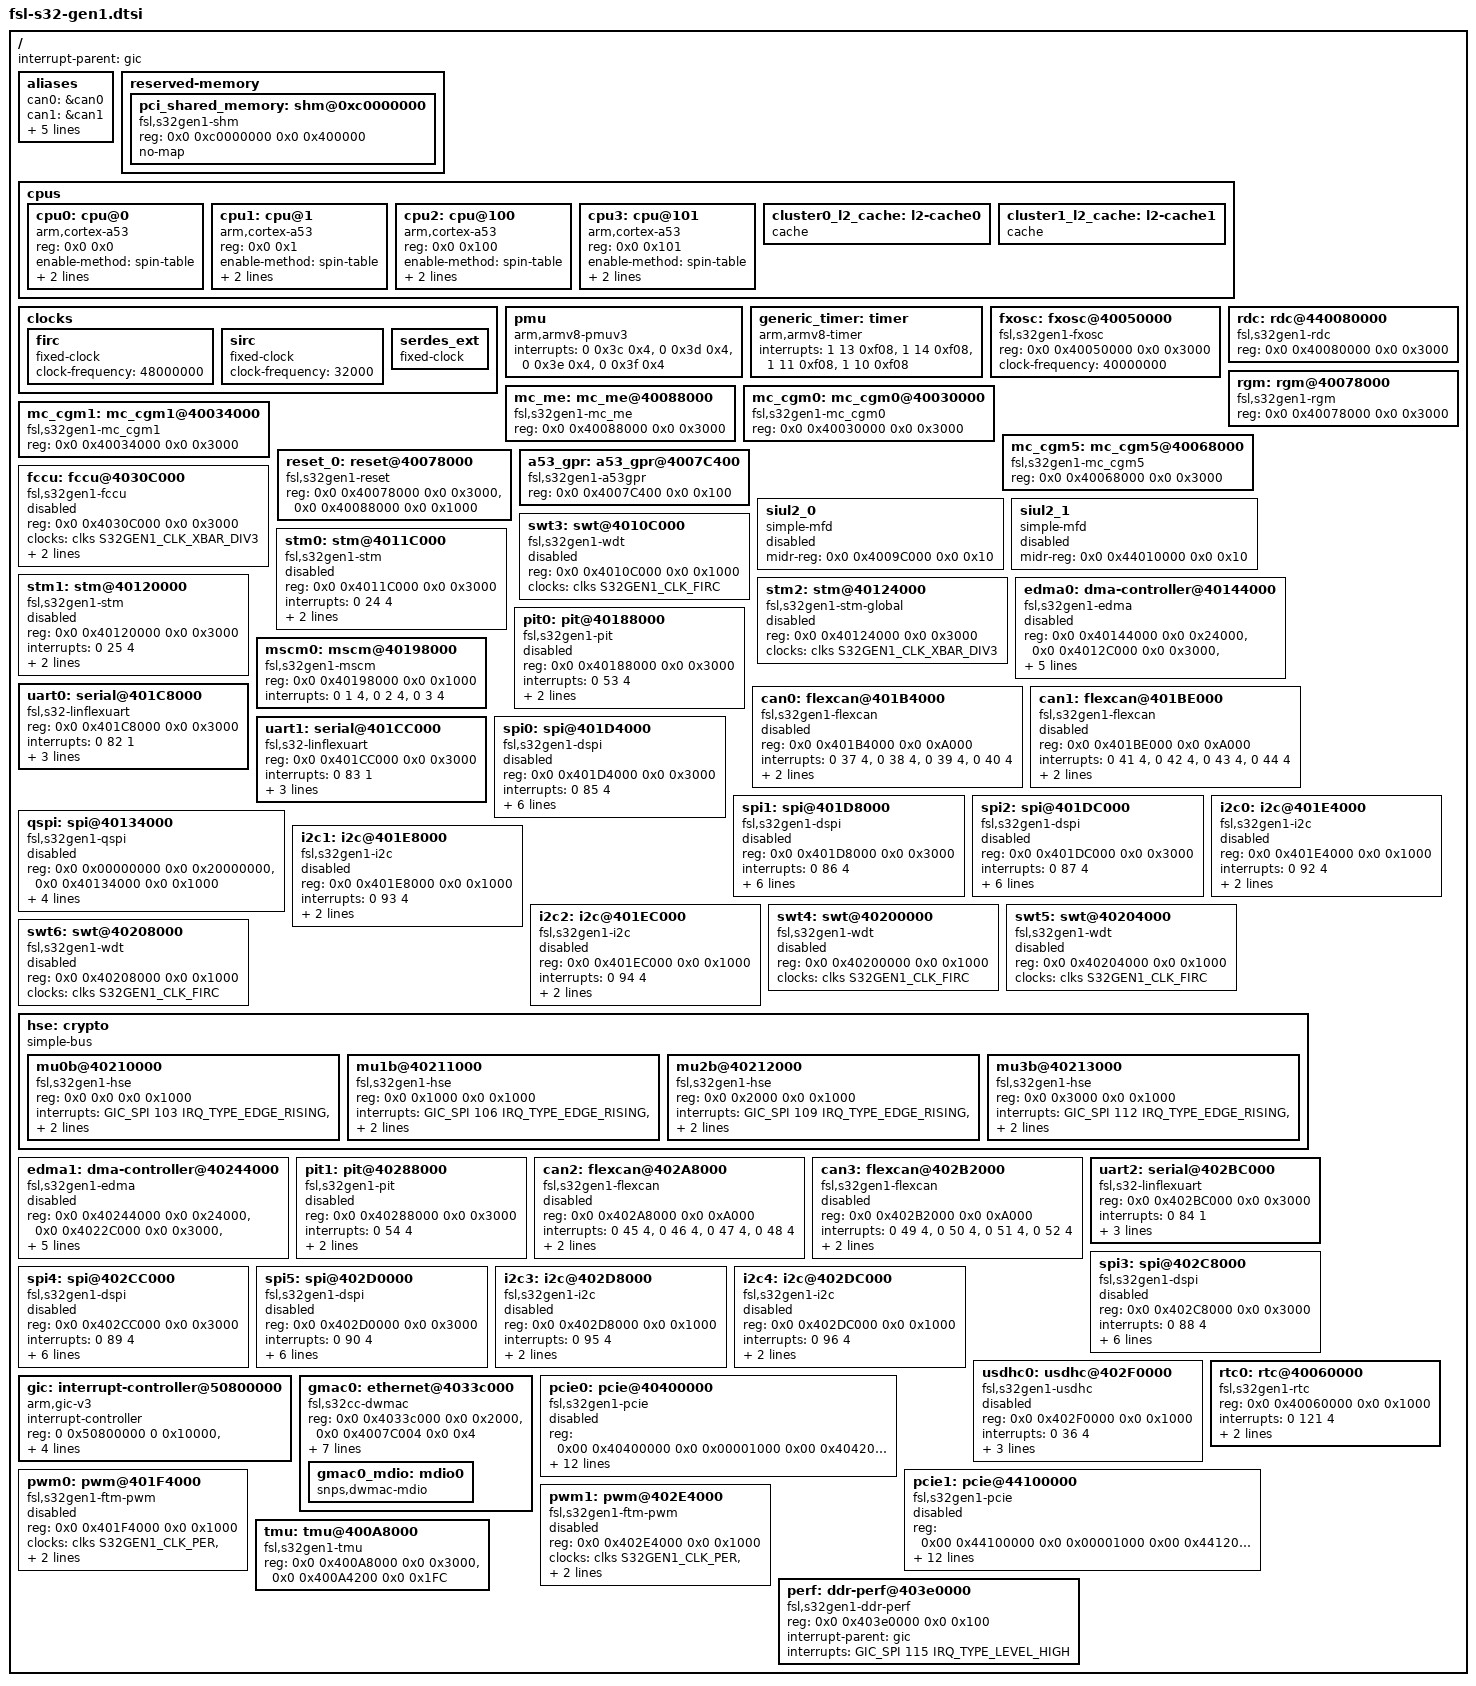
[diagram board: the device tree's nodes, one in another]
/*
 * Copyright 2017-2020 NXP
 *
 * This program is free software; you can redistribute it and/or modify
 * it under the terms of the GNU General Public License as published by
 * the Free Software Foundation; either version 2 of the License, or
 * (at your option) any later version.
 */

#include <dt-bindings/interrupt-controller/arm-gic.h>
#include <dt-bindings/clock/s32gen1-clock.h>

/memreserve/ 0x8000fff8 0x00010000;

/ {
	interrupt-parent = <&gic>;
	#address-cells = <2>;
	#size-cells = <2>;

	aliases {
		can0 = &can0;
		can1 = &can1;
		can2 = &can2;
		can3 = &can3;

		serial0 = &uart0;
		serial1 = &uart1;
		serial2 = &uart2;
	};

	reserved-memory {
		#address-cells = <2>;
		#size-cells = <2>;
		ranges;

		/* 4Mb shared memory for PCIe shared mem transfers, EP mode */
		pci_shared_memory: shm@0xc0000000 {
			compatible = "fsl,s32gen1-shm";
			reg = <0x0 0xc0000000 0x0 0x400000>;    /* 4 MB */
			no-map;
		};
	};

	cpus {
		#address-cells = <2>;
		#size-cells = <0>;

		cpu0: cpu@0 {
			device_type = "cpu";
			compatible = "arm,cortex-a53";
			reg = <0x0 0x0>;
			enable-method = "spin-table";
			cpu-release-addr = <0x0 0x00>;
		};
		cpu1: cpu@1 {
			device_type = "cpu";
			compatible = "arm,cortex-a53";
			reg = <0x0 0x1>;
			enable-method = "spin-table";
			cpu-release-addr = <0x0 0x00>;
		};
		cpu2: cpu@100 {
			device_type = "cpu";
			compatible = "arm,cortex-a53";
			reg = <0x0 0x100>;
			enable-method = "spin-table";
			cpu-release-addr = <0x0 0x00>;
		};
		cpu3: cpu@101 {
			device_type = "cpu";
			compatible = "arm,cortex-a53";
			reg = <0x0 0x101>;
			enable-method = "spin-table";
			cpu-release-addr = <0x0 0x00>;
		};

		cluster0_l2_cache: l2-cache0 {
			compatible = "cache";
			status = "disabled";
		};

		cluster1_l2_cache: l2-cache1 {
			compatible = "cache";
			status = "disabled";
		};

	};

	clocks {
		#address-cells = <1>;
		#size-cells = <0>;

		firc {
			compatible = "fixed-clock";
			clock-frequency = <48000000>;
			#clock-cells = <0>;
		};
		sirc {
			compatible = "fixed-clock";
			clock-frequency = <32000>;
			#clock-cells = <0>;
		};
		serdes_ext: serdes_ext {
			compatible = "fixed-clock";
			#clock-cells = <0>;
		};
	};

	pmu {
		compatible = "arm,armv8-pmuv3";
		interrupts = <0 0x3c 0x4>,
			     <0 0x3d 0x4>,
			     <0 0x3e 0x4>,
			     <0 0x3f 0x4>;
	};

	generic_timer: timer {
		compatible = "arm,armv8-timer";
		interrupts = <1 13 0xf08>,
			     <1 14 0xf08>,
			     <1 11 0xf08>,
			     <1 10 0xf08>;
	};

	fxosc: fxosc@40050000 {
		compatible = "fsl,s32gen1-fxosc";
		reg = <0x0 0x40050000 0x0 0x3000>;
		clock-frequency = <40000000>;
		#clock-cells = <1>;
	};

	rdc: rdc@440080000 {
		compatible = "fsl,s32gen1-rdc";
		reg = <0x0 0x40080000 0x0 0x3000>;
	};

	rgm: rgm@40078000 {
		compatible = "fsl,s32gen1-rgm";
		reg = <0x0 0x40078000 0x0 0x3000>;
	};

	mc_me: mc_me@40088000 {
		compatible = "fsl,s32gen1-mc_me";
		reg = <0x0 0x40088000 0x0 0x3000>;
	};

	mc_cgm0: mc_cgm0@40030000 {
		compatible = "fsl,s32gen1-mc_cgm0";
		reg = <0x0 0x40030000 0x0 0x3000>;
	};

	mc_cgm1: mc_cgm1@40034000 {
		compatible = "fsl,s32gen1-mc_cgm1";
		reg = <0x0 0x40034000 0x0 0x3000>;
	};

	mc_cgm5: mc_cgm5@40068000 {
		compatible = "fsl,s32gen1-mc_cgm5";
		reg = <0x0 0x40068000 0x0 0x3000>;
	};

	reset_0: reset@40078000 {
		compatible = "fsl,s32gen1-reset";
		      /* MC RGM */
		reg = <0x0 0x40078000 0x0 0x3000>,
		      /* MC ME */
		      <0x0 0x40088000 0x0 0x1000>;
	};

	a53_gpr: a53_gpr@4007C400 {
		compatible = "fsl,s32gen1-a53gpr";
		reg = <0x0 0x4007C400 0x0 0x100>;
	};

	fccu: fccu@4030C000 {
		compatible = "fsl,s32gen1-fccu";
		reg = <0x0 0x4030C000 0x0 0x3000>;
		clocks = <&clks S32GEN1_CLK_XBAR_DIV3>;
		clock-names = "fccu";
		/* Address offset and configuration value for */
		/* NCF_E1 and NCFS_CFG2*/
		cfg_reg_off = <0x98 0x54>;
		cfg_reg_val = <0x78 0x1540>;
		status = "disabled";
	};

	siul2_0 {
		compatible = "simple-mfd";
		#address-cells = <2>;
		#size-cells = <2>;
		/* MIDR registers
		 * They physically exist in EIRQ
		 * addr space but they don't belong
		 * to GPIO
		 */
		midr-reg = <0x0 0x4009C000 0x0 0x10>;
		status = "disabled";
	};

	siul2_1 {
		compatible = "simple-mfd";
		#address-cells = <2>;
		#size-cells = <2>;
		/* MIDR registers
		 * They physically exist in EIRQ
		 * addr space but they don't belong
		 * to GPIO
		 */
		midr-reg = <0x0 0x44010000 0x0 0x10>;
		status = "disabled";
	};

	swt3: swt@4010C000 {
		compatible = "fsl,s32gen1-wdt";
		reg = <0x0 0x4010C000 0x0 0x1000>;
		clocks = <&clks S32GEN1_CLK_FIRC>;
		clock-names = "swt";
		status = "disabled";
	};

	stm0: stm@4011C000{
		compatible = "fsl,s32gen1-stm";
		reg = <0x0 0x4011C000 0x0 0x3000>;
		interrupts= <0 24 4>;
		clocks = <&clks S32GEN1_CLK_XBAR_DIV3>;
		clock-names = "stm";
		cpu = <2>;
		status = "disabled";
	};

	stm1: stm@40120000{
		compatible = "fsl,s32gen1-stm";
		reg = <0x0 0x40120000 0x0 0x3000>;
		interrupts= <0 25 4>;
		clocks = <&clks S32GEN1_CLK_XBAR_DIV3>;
		clock-names = "stm";
		cpu = <3>;
		status = "disabled";
	};

	stm2: stm@40124000{
		compatible = "fsl,s32gen1-stm-global";
		reg = <0x0 0x40124000 0x0 0x3000>;
		clocks = <&clks S32GEN1_CLK_XBAR_DIV3>;
		clock-names = "stm";
		status = "disabled";
	};

	edma0: dma-controller@40144000 {
		#dma-cells = <2>;
		compatible = "fsl,s32gen1-edma";
		reg = <0x0 0x40144000 0x0 0x24000>,
		      <0x0 0x4012C000 0x0 0x3000>,
		      <0x0 0x40130000 0x0 0x3000>;
		dma-channels = <32>;
		interrupts = <0 8 4>,
			     <0 9 4>,
			     <0 10 4>;
		interrupt-names = "edma-tx_0-15",
				  "edma-tx_16-31",
				  "edma-err";
		clock-names = "dmamux0", "dmamux1";
		clocks = <&clks S32GEN1_CLK_XBAR>,
			 <&clks S32GEN1_CLK_XBAR>;
		status = "disabled";
	};

	pit0: pit@40188000{
		compatible = "fsl,s32gen1-pit";
		reg = <0x0 0x40188000 0x0 0x3000>;
		interrupts= <0 53 4>;
		clocks = <&clks S32GEN1_CLK_XBAR_DIV3>;
		clock-names = "pit";
		cpu = <0>;
		status = "disabled";
	};

	mscm0: mscm@40198000  {
		compatible = "fsl,s32gen1-mscm";

		reg = <0x0 0x40198000 0x0 0x1000>;

		/* CPU2CPU interrupts */
		interrupts = <0 1 4>, // CPU to M7/A53/R52 interrupt#0 (GIC 33)
			     <0 2 4>, // CPU to M7/A53/R52 interrupt#1 (GIC 34)
			     <0 3 4>; // CPU to M7/A53/R52 interrupt#2 (GIC 35)
	};

	can0: flexcan@401B4000{
		compatible = "fsl,s32gen1-flexcan";
		reg = <0x0 0x401B4000 0x0 0xA000>;
		interrupts = <0 37 4>,
			     <0 38 4>,
			     <0 39 4>,
			     <0 40 4>;
		interrupt-names = "state", "berr", "mb_0-7", "mb_8-127";
		clocks = <&clks S32GEN1_CLK_CAN>,
			 <&clks S32GEN1_CLK_XBAR_DIV3>;
		clock-names = "per", "ipg";
		status = "disabled";
	};

	can1: flexcan@401BE000{
		compatible = "fsl,s32gen1-flexcan";
		reg = <0x0 0x401BE000 0x0 0xA000>;
		interrupts = <0 41 4>,
			     <0 42 4>,
			     <0 43 4>,
			     <0 44 4>;
		interrupt-names = "state", "berr", "mb_0-7", "mb_8-127";
		clocks = <&clks S32GEN1_CLK_CAN>,
			 <&clks S32GEN1_CLK_XBAR_DIV3>;
		clock-names = "per", "ipg";
		status = "disabled";
	};

	uart0:serial@401C8000 {
		compatible = "fsl,s32-linflexuart";
		reg = <0x0 0x401C8000 0x0 0x3000>;
		interrupts = <0 82 1>;
		clocks = <&clks S32GEN1_CLK_LIN_BAUD>,
			 <&clks S32GEN1_CLK_LIN>;
		clock-names = "lin", "ipg";
		dmas = <&edma0 0 4>,
		       <&edma0 0 3>;
		dma-names = "rx", "tx";
	};

	uart1:serial@401CC000 {
		compatible = "fsl,s32-linflexuart";
		reg = <0x0 0x401CC000 0x0 0x3000>;
		interrupts = <0 83 1>;
		clocks = <&clks S32GEN1_CLK_LIN_BAUD>,
			 <&clks S32GEN1_CLK_LIN>;
		clock-names = "lin", "ipg";
		dmas = <&edma0 0 6>,
		       <&edma0 0 5>;
		dma-names = "rx", "tx";
	};

	spi0: spi@401D4000 {
		compatible = "fsl,s32gen1-dspi";
		reg = <0x0 0x401D4000 0x0 0x3000>;
		interrupts = <0 85 4>;
		clocks = <&clks S32GEN1_CLK_DSPI>;
		clock-names = "dspi";
		spi-num-chipselects = <8>;
		bus-num = <0>;
		spi-fifo-size = <5>;
		spi-cpol;
		spi-cpha;
		status = "disabled";
	};

	spi1: spi@401D8000 {
		compatible = "fsl,s32gen1-dspi";
		reg = <0x0 0x401D8000 0x0 0x3000>;
		interrupts = <0 86 4>;
		clocks = <&clks S32GEN1_CLK_DSPI>;
		clock-names = "dspi";
		spi-num-chipselects = <5>;
		bus-num = <1>;
		spi-fifo-size = <5>;
		spi-cpol;
		spi-cpha;
		status = "disabled";
	};

	spi2: spi@401DC000 {
		compatible = "fsl,s32gen1-dspi";
		reg = <0x0 0x401DC000 0x0 0x3000>;
		interrupts = <0 87 4>;
		clocks = <&clks S32GEN1_CLK_DSPI>;
		clock-names = "dspi";
		spi-num-chipselects = <5>;
		bus-num = <2>;
		spi-fifo-size = <5>;
		spi-cpol;
		spi-cpha;
		status = "disabled";
	};

	qspi: spi@40134000 {
		compatible = "fsl,s32gen1-qspi";
		#address-cells = <1>;
		#size-cells = <0>;
		reg = <0x0 0x00000000 0x0 0x20000000>,
			<0x0 0x40134000 0x0 0x1000>;
		reg-names = "QuadSPI-memory", "QuadSPI";
		interrupts = <0 32 4>;
		clocks = <&clks S32GEN1_CLK_QSPI_SEL>,
			   <&clks S32GEN1_CLK_QSPI_2X>,
			   <&clks S32GEN1_CLK_QSPI_1X>;
		clock-names = "qspi_en", "qspi";
		status = "disabled";
	};

	i2c0: i2c@401E4000 {
		#address-cells = <1>;
		#size-cells = <0>;
		compatible = "fsl,s32gen1-i2c";
		reg = <0x0 0x401E4000 0x0 0x1000>;
		interrupts =<0 92 4>;
		clocks = <&clks S32GEN1_CLK_XBAR_DIV3>;
		clock-names = "ipg";
		dmas = <&edma0 0 16>,
		       <&edma0 0 17>;
		dma-names = "rx","tx";
		status = "disabled";
	};

	i2c1: i2c@401E8000 {
		#address-cells = <1>;
		#size-cells = <0>;
		compatible = "fsl,s32gen1-i2c";
		reg = <0x0 0x401E8000 0x0 0x1000>;
		interrupts =<0 93 4>;
		clocks = <&clks S32GEN1_CLK_XBAR_DIV3>;
		clock-names = "ipg";
		dmas = <&edma0 0 18>,
		       <&edma0 0 19>;
		dma-names = "rx","tx";
		status = "disabled";
	};

	i2c2: i2c@401EC000 {
		#address-cells = <1>;
		#size-cells = <0>;
		compatible = "fsl,s32gen1-i2c";
		reg = <0x0 0x401EC000 0x0 0x1000>;
		interrupts =<0 94 4>;
		clocks = <&clks S32GEN1_CLK_XBAR_DIV3>;
		clock-names = "ipg";
		dmas = <&edma1 1 16>,
		       <&edma1 1 17>;
		dma-names = "rx","tx";
		status = "disabled";
	};

	swt4: swt@40200000 {
		compatible = "fsl,s32gen1-wdt";
		reg = <0x0 0x40200000 0x0 0x1000>;
		clocks = <&clks S32GEN1_CLK_FIRC>;
		clock-names = "swt";
		status = "disabled";
	};

	swt5: swt@40204000 {
		compatible = "fsl,s32gen1-wdt";
		reg = <0x0 0x40204000 0x0 0x1000>;
		clocks = <&clks S32GEN1_CLK_FIRC>;
		clock-names = "swt";
		status = "disabled";
	};

	swt6: swt@40208000 {
		compatible = "fsl,s32gen1-wdt";
		reg = <0x0 0x40208000 0x0 0x1000>;
		clocks = <&clks S32GEN1_CLK_FIRC>;
		clock-names = "swt";
		status = "disabled";
	};

	hse: crypto {
		compatible = "simple-bus";
		#address-cells = <2>;
		#size-cells = <2>;
		#interrupt-cells = <3>;
		ranges = <0x0 0x0 0x0 0x40210000 0x0 0x4000>;

		mu0b@40210000 {
			compatible = "fsl,s32gen1-hse";
			reg = <0x0 0x0 0x0 0x1000>;
			interrupts = <GIC_SPI 103 IRQ_TYPE_EDGE_RISING>, /* GIC 135 */
			             <GIC_SPI 104 IRQ_TYPE_EDGE_RISING>, /* GIC 136 */
			             <GIC_SPI 105 IRQ_TYPE_EDGE_RISING>; /* GIC 137 */
			interrupt-names = "hse-mu0b-ack",
			                  "hse-mu0b-rx",
			                  "hse-mu0b-err";
		};
		mu1b@40211000 {
			compatible = "fsl,s32gen1-hse";
			reg = <0x0 0x1000 0x0 0x1000>;
			interrupts = <GIC_SPI 106 IRQ_TYPE_EDGE_RISING>, /* GIC 138 */
			             <GIC_SPI 107 IRQ_TYPE_EDGE_RISING>, /* GIC 139 */
			             <GIC_SPI 108 IRQ_TYPE_EDGE_RISING>; /* GIC 140 */
			interrupt-names = "hse-mu1b-ack",
			                  "hse-mu1b-rx",
			                  "hse-mu1b-err";
		};
		mu2b@40212000 {
			compatible = "fsl,s32gen1-hse";
			reg = <0x0 0x2000 0x0 0x1000>;
			interrupts = <GIC_SPI 109 IRQ_TYPE_EDGE_RISING>, /* GIC 141 */
			             <GIC_SPI 110 IRQ_TYPE_EDGE_RISING>, /* GIC 142 */
			             <GIC_SPI 111 IRQ_TYPE_EDGE_RISING>; /* GIC 143 */
			interrupt-names = "hse-mu2b-ack",
			                  "hse-mu2b-rx",
			                  "hse-mu2b-err";
		};
		mu3b@40213000 {
			compatible = "fsl,s32gen1-hse";
			reg = <0x0 0x3000 0x0 0x1000>;
			interrupts = <GIC_SPI 112 IRQ_TYPE_EDGE_RISING>, /* GIC 144 */
			             <GIC_SPI 113 IRQ_TYPE_EDGE_RISING>, /* GIC 145 */
			             <GIC_SPI 114 IRQ_TYPE_EDGE_RISING>; /* GIC 146 */
			interrupt-names = "hse-mu3b-ack",
			                  "hse-mu3b-rx",
			                  "hse-mu3b-err";
		};
	};

	edma1: dma-controller@40244000 {
		#dma-cells = <2>;
		compatible = "fsl,s32gen1-edma";
		reg = <0x0 0x40244000 0x0 0x24000>,
		      <0x0 0x4022C000 0x0 0x3000>,
		      <0x0 0x40230000 0x0 0x3000>;
		dma-channels = <32>;
		interrupts = <0 11 4>,
			     <0 12 4>,
			     <0 13 4>;
		interrupt-names = "edma-tx_0-15",
				  "edma-tx_16-31",
				  "edma-err";
		clock-names = "dmamux0", "dmamux1";
		clocks = <&clks S32GEN1_CLK_XBAR>,
			 <&clks S32GEN1_CLK_XBAR>;
		status = "disabled";
	};

	pit1: pit@40288000{
		compatible = "fsl,s32gen1-pit";
		reg = <0x0 0x40288000 0x0 0x3000>;
		interrupts= <0 54 4>;
		cpu = <1>;
		clocks = <&clks S32GEN1_CLK_XBAR_DIV3>;
		clock-names = "pit";
		status = "disabled";
	};

	can2: flexcan@402A8000{
		compatible = "fsl,s32gen1-flexcan";
		reg = <0x0 0x402A8000 0x0 0xA000>;
		interrupts = <0 45 4>,
			     <0 46 4>,
			     <0 47 4>,
			     <0 48 4>;
		interrupt-names = "state", "berr", "mb_0-7", "mb_8-127";
		clocks = <&clks S32GEN1_CLK_CAN>,
			 <&clks S32GEN1_CLK_XBAR_DIV3>;
		clock-names = "per", "ipg";
		status = "disabled";
	};

	can3: flexcan@402B2000{
		compatible = "fsl,s32gen1-flexcan";
		reg = <0x0 0x402B2000 0x0 0xA000>;
		interrupts = <0 49 4>,
			     <0 50 4>,
			     <0 51 4>,
			     <0 52 4>;
		interrupt-names = "state", "berr", "mb_0-7", "mb_8-127";
		clocks = <&clks S32GEN1_CLK_CAN>,
			 <&clks S32GEN1_CLK_XBAR_DIV3>;
		clock-names = "per", "ipg";
		status = "disabled";
	};

	uart2:serial@402BC000 {
		compatible = "fsl,s32-linflexuart";
		reg = <0x0 0x402BC000 0x0 0x3000>;
		interrupts = <0 84 1>;
		clocks = <&clks S32GEN1_CLK_LIN_BAUD>,
			 <&clks S32GEN1_CLK_LIN>;
		clock-names = "lin", "ipg";
		dmas = <&edma1 1 4>,
		       <&edma1 1 3>;
		dma-names = "rx", "tx";
	};

	spi3: spi@402C8000 {
		compatible = "fsl,s32gen1-dspi";
		reg = <0x0 0x402C8000 0x0 0x3000>;
		interrupts = <0 88 4>;
		clocks = <&clks S32GEN1_CLK_DSPI>;
		clock-names = "dspi";
		spi-num-chipselects = <5>;
		bus-num = <3>;
		spi-fifo-size = <5>;
		spi-cpol;
		spi-cpha;
		status = "disabled";
	};

	spi4: spi@402CC000 {
		compatible = "fsl,s32gen1-dspi";
		reg = <0x0 0x402CC000 0x0 0x3000>;
		interrupts = <0 89 4>;
		clocks = <&clks S32GEN1_CLK_DSPI>;
		clock-names = "dspi";
		spi-num-chipselects = <5>;
		bus-num = <4>;
		spi-fifo-size = <5>;
		spi-cpol;
		spi-cpha;
		status = "disabled";
	};

	spi5: spi@402D0000 {
		compatible = "fsl,s32gen1-dspi";
		reg = <0x0 0x402D0000 0x0 0x3000>;
		interrupts = <0 90 4>;
		clocks = <&clks S32GEN1_CLK_DSPI>;
		clock-names = "dspi";
		spi-num-chipselects = <5>;
		bus-num = <5>;
		spi-fifo-size = <5>;
		spi-cpol;
		spi-cpha;
		status = "disabled";
	};

	i2c3: i2c@402D8000 {
		#address-cells = <1>;
		#size-cells = <0>;
		compatible = "fsl,s32gen1-i2c";
		reg = <0x0 0x402D8000 0x0 0x1000>;
		interrupts =<0 95 4>;
		clocks = <&clks S32GEN1_CLK_XBAR_DIV3>;
		clock-names = "ipg";
		dmas = <&edma1 1 18>,
		       <&edma1 1 19>;
		dma-names = "rx","tx";
		status = "disabled";
	};

	i2c4: i2c@402DC000 {
		#address-cells = <1>;
		#size-cells = <0>;
		compatible = "fsl,s32gen1-i2c";
		reg = <0x0 0x402DC000 0x0 0x1000>;
		interrupts =<0 96 4>;
		clocks = <&clks S32GEN1_CLK_XBAR_DIV3>;
		clock-names = "ipg";
		dmas = <&edma1 1 20>,
		       <&edma1 1 21>;
		dma-names = "rx","tx";
		status = "disabled";
	};

	usdhc0: usdhc@402F0000{
		compatible = "fsl,s32gen1-usdhc";
		reg = <0x0 0x402F0000 0x0 0x1000>;
		interrupts = <0 36 4>;
		clocks = <&clks S32GEN1_CLK_XBAR_DIV3>,
			 <&clks S32GEN1_CLK_XBAR>,
			 <&clks S32GEN1_CLK_SDHC>;
		clock-names = "ipg", "ahb", "per";
		bus-width = <8>;
		status = "disabled";
	};

	gic: interrupt-controller@50800000 {
		compatible = "arm,gic-v3";
		#interrupt-cells = <3>;
		#address-cells = <2>;
		#size-cells = <2>;
		interrupt-controller;
		reg = <0 0x50800000 0 0x10000>,
		      <0 0x50880000 0 0x200000>,
		      <0 0x50400000 0 0x2000>,
		      <0 0x50410000 0 0x2000>,
		      <0 0x50420000 0 0x2000>;
		interrupts = <1 9 0xf04>;
	};

	rtc0: rtc@40060000 {
		compatible = "fsl,s32gen1-rtc";
		#interrupt-cells = <3>;
		reg = <0x0 0x40060000 0x0 0x1000>;
		interrupts = <0 121 4>;	// RTC irq - GIC 153
		/* Input clock selection: use the 48MHz FIRC with DIV512,
		 * for a roll-over time of just under 13 hours.
		 */
		clksel = <2>;		// 2: FIRC; 0: SIRC
		dividers = <1 0>;	// div512 enabled; div32 disabled
	};

	gmac0: ethernet@4033c000 {
		compatible = "fsl,s32cc-dwmac";
		reg = <0x0 0x4033c000 0x0 0x2000>, /* gmac IP */
		      <0x0 0x4007C004 0x0 0x4>;    /* S32 CTRL_STS reg */
		interrupt-parent = <&gic>;
		interrupts = <0 57 4>;
		interrupt-names = "macirq";
		tx-fifo-depth = <20480>;
		rx-fifo-depth = <20480>;
		clocks = <&clks S32GEN1_CLK_XBAR>, <&clks S32GEN1_CLK_XBAR>,
			     <&clks S32GEN1_CLK_GMAC_0_TX>;
		clock-names = "stmmaceth", "pclk", "tx";
		gmac0_mdio: mdio0 {
			compatible = "snps,dwmac-mdio";
			#address-cells = <1>;
			#size-cells = <0>;
		};
	};

	pcie0: pcie@40400000 {
		compatible = "fsl,s32gen1-pcie";
		reg = <0x00 0x40400000 0x0 0x00001000   /* dbi registers */
		       0x00 0x40420000 0x0 0x00001000   /* dbi2 registers */
		       0x00 0x40460000 0x0 0x00001000   /* atu registers */
		       0x00 0x40470000 0x0 0x00001000   /* dma registers */
		       0x00 0x40480000 0x0 0x00004000   /* ctrl registers */
		       0x58 0x00000000 0x0 0x00002000   /* RC config space */
		       0x58 0x40000000 0x0 0x40000000>; /* EP addr space, 1GB */
		reg-names = "dbi", "dbi2", "atu", "dma", "ctrl",
				"config", "addr_space";
		#address-cells = <3>;
		#size-cells = <2>;
		device_type = "pci";
		device_id = <0>;
		ranges =
		      /* downstream I/O */
		      <0x81000000 0x0 0x00000000 0x58 0x00003000 0x0 0x00010000
		      /* non-prefetchable memory */
		      0x82000000 0x0 0x00013000 0x58 0x00013000 0x0 0x40000000>;

		num-lanes = <2>;
		max-link-speed = <3>;
		bus-range = <0x0 0xff>;
		interrupts =  <0 124 4>, <0 123 4>, <0 125 4>,
					<0 126 4>, <0 127 4>, <0 132 4>,
					<0 133 4>, <0 134 4>;
		interrupt-names = "link_req_stat", "dma","msi",
					"phy_link_down", "phy_link_up", "misc",
					"pcs", "tlp_req_no_comp";
		#interrupt-cells = <1>;
		interrupt-map-mask = <0 0 0 0x7>;
		interrupt-map = <0 0 0 1 &gic 0 0 0 128 4>,
					<0 0 0 2 &gic 0 0 0 129 4>,
					<0 0 0 3 &gic 0 0 0 130 4>,
					<0 0 0 4 &gic 0 0 0 131 4>;

		/* EP mode only */
		num-ib-windows = <6>;
		num-ob-windows = <6>;

		status = "disabled";
	};

	pcie1: pcie@44100000 {
		compatible = "fsl,s32gen1-pcie";
		reg = <0x00 0x44100000 0x0 0x00001000   /* dbi registers */
		       0x00 0x44120000 0x0 0x00001000   /* dbi2 registers */
		       0x00 0x44160000 0x0 0x00001000   /* atu registers */
		       0x00 0x44170000 0x0 0x00001000   /* dma registers */
		       0x00 0x44180000 0x0 0x00004000   /* ctrl registers */
		       0x48 0x00000000 0x0 0x00002000   /* RC config space */
		       0x48 0x40000000 0x0 0x40000000>; /* EP addr space, 1GB */
		reg-names = "dbi", "dbi2", "atu", "dma", "ctrl",
				"config", "addr_space";
		#address-cells = <3>;
		#size-cells = <2>;
		device_type = "pci";
		device_id = <1>;
		ranges =
		      /* downstream I/O */
		      <0x81000000 0x0 0x00000000 0x48 0x00003000 0x0 0x00010000
		      /* non-prefetchable memory */
		      0x82000000 0x0 0x00013000 0x48 0x00013000 0x0 0x40000000>;

		num-lanes = <1>;
		max-link-speed = <3>;
		bus-range = <0x0 0xff>;
		interrupts =  <0 215 4>, <0 214 4>, <0 216 4>,
					<0 217 4>, <0 218 4>, <0 223 4>,
					<0 224 4>, <0 225 4>;
		interrupt-names = "link_req_stat", "dma","msi",
					"phy_link_down", "phy_link_up", "misc",
					"pcs", "tlp_req_no_comp";
		#interrupt-cells = <1>;
		interrupt-map-mask = <0 0 0 0x7>;
		interrupt-map = <0 0 0 1 &gic 0 0 0 219 4>,
					<0 0 0 2 &gic 0 0 0 220 4>,
					<0 0 0 3 &gic 0 0 0 221 4>,
					<0 0 0 4 &gic 0 0 0 222 4>;

		/* EP mode only */
		num-ib-windows = <6>;
		num-ob-windows = <6>;

		status = "disabled";
	};

	pwm0: pwm@401F4000 {
		compatible = "fsl,s32gen1-ftm-pwm";
		#pwm-cells = <3>;
		reg = <0x0 0x401F4000 0x0 0x1000>;
		clock-names = "ftm_sys", "ftm_ext",
			      "ftm_fix", "ftm_cnt_clk_en";
		clocks = <&clks S32GEN1_CLK_PER>,
			 <&clks S32GEN1_CLK_FTM0_REF>,
			 <&clks S32GEN1_CLK_PER>,
			 <&clks S32GEN1_CLK_PER>;
		status = "disabled";
	};

	pwm1: pwm@402E4000 {
		compatible = "fsl,s32gen1-ftm-pwm";
		#pwm-cells = <3>;
		reg = <0x0 0x402E4000 0x0 0x1000>;
		clock-names = "ftm_sys", "ftm_ext",
			      "ftm_fix", "ftm_cnt_clk_en";
		clocks = <&clks S32GEN1_CLK_PER>,
			 <&clks S32GEN1_CLK_FTM1_REF>,
			 <&clks S32GEN1_CLK_PER>,
			 <&clks S32GEN1_CLK_PER>;
		status = "disabled";
	};

	tmu: tmu@400A8000 {
		compatible = "fsl,s32gen1-tmu";
		reg = <0x0 0x400A8000 0x0 0x3000>,
			<0x0 0x400A4200 0x0 0x1FC>;
		status = "okay";
	};

	perf: ddr-perf@403e0000 {
		compatible = "fsl,s32gen1-ddr-perf";
		reg = <0x0 0x403e0000 0x0 0x100>;
		interrupt-parent = <&gic>;
		interrupts = <GIC_SPI 115 IRQ_TYPE_LEVEL_HIGH>; /* GIC 147 */
	};

};

&cluster0_l2_cache {
	status = "okay";
};

&cluster1_l2_cache {
	status = "okay";
};

&cpu0 {
	next-level-cache = <&cluster0_l2_cache>;
};

&cpu1 {
	next-level-cache = <&cluster0_l2_cache>;
};

&cpu2 {
	next-level-cache = <&cluster1_l2_cache>;
};

&cpu3 {
	next-level-cache = <&cluster1_l2_cache>;
};
